# MEC1704Q register map
Vendor: Microchip Technology; Series: MEC1704; File version: 0
CPU: CM4 r1p0, little endian, MPU, FPU, 3 interrupt priority bits, 155 interrupts
Registers are 32-bit, read-write, reset 0x0 unless marked. A register's access mark holds for its fields unless they carry their own. Offsets are from the block's base; [hi:lo] are bit positions.

## RC_ID0 — This interface provides a single pin interface which can discriminate a number of quantized RC constants.
Base 0x40001400; register names take the prefix RC_ID_
Same registers: RC_ID1 0x40001480, RC_ID2 0x40001500
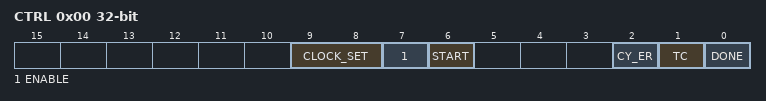
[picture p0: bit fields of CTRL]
0x00 CTRL — RC_ID Control Register
  [9:8] CLOCK_SET — This field selects the frequency of the Counter circuit clock. This field must retain the same value as long as the ENABLE bit in this register is 1.
  [7] ENABLE — Clearing the bit to 0 causes the RC_ID interface to enter the Reset state, gating its clocks, clearing the status bits in this register and entering into its lowest power state. Setting this bit to 1 causes the RC_ID interface to enter the Armed phase of an RC_ID measurement.
  [6] START — Setting this bit to 1 initiates the Discharged phase of an RC_ID measurement.
  [2] CY_ER — This bit is 1 if an RC_ID measurement encountered an error and the reading in the RC_ID Data Register is invalid. This bit is cleared to 0 when the RC_ID interface is in the Reset phase.
  [1] TC — This bit is cleared to 0 when the RC_ID interface is in the Reset phase, and set to 1 when the interface completes the Discharged phase of an RC_ID measurement.
  [0] DONE — This bit is cleared to 0 when the RC_ID interface is in the Reset phase, and set to 1 when the interface completes an RC_ID measurement.
0x04 DAT — Reads of this register provide the result of an RC_ID measurement.
  [15:0] RCID_DATA

## KMS — The Keyboard Scan Interface block provides a register interface to the EC to directly scan an external keyboard matrix of size up to 18x8.
Base 0x40009C00
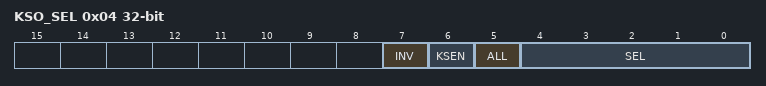
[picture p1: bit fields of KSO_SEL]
0x04 KSO_SEL — KSO Select and control
  [7] INV — 0= KSO[x] driven low when selected, 1= KSO[x] driven high when selected.
  [6] KSEN — 0= Keyboard scan enabled, 1= Keyboard scan disabled. All KSO output buffers disabled.
  [5] ALL — 0=When key scan is enabled, KSO output controlled by the KSO_SELECT field. 1=KSO[x] driven high when selected.
  [4:0] SEL — This field selects a KSO line (00000b = KSO[0] etc.) for output according to the value off KSO_INVERT in this register.
0x08 KSI ro — [7:0] This field returns the current state of the KSI pins.
0x0C KSI_STS — [7:0] Each bit in this field is set on the falling edge of the corresponding KSI input pin. A KSI interrupt is generated when its corresponding status bit and interrupt enable bit are both set. KSI interrupts are logically ORed together to produce KSC_INT and KSC_INT_WAKE. Writing a '1' to a bit will clear it. Writing a '0' to a bit has no effect.
0x10 KSI_IEN — [7:0] Each bit in KSI_IEN enables interrupt generation due to highto-low transition on a KSI input. An interrupt is generated when the corresponding bits in KSI_STATUS and KSI_INT_EN are both set.
0x14 EXT_CTRL — [0:0] PREDRIVE_ENABLE enables the. PREDRIVE mode to actively drive the KSO pins high for approximately 100ns before switching to open-drain operation. 0=Disable predrive on KSO pins. 1=Enable predrive on KSO pins.

## GP_SPI0 — The General Purpose Serial Peripheral Interface (GP-SPI) may be used to communicate with various peripheral devices, e.g., EEPROMS, DACs, ADCs, that use a standard Serial Peripheral Interface.
Base 0x40009400; register names take the prefix GP_SPI_
Same registers: GP_SPI1 0x40009480
0x00 ENABLE reset 0xF — [0:0] 1=Enabled. The device is fully operational. 0=Disabled. Clocks are gated to conserve power and the SPDOUT and SPI_CLK signals are set to their inactive state
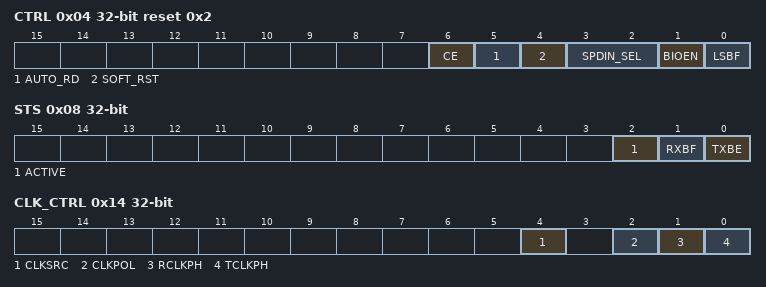
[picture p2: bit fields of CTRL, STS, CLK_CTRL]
0x04 CTRL reset 0x2 — SPI Control
  [6] CE — SPI Chip Select Enable. 1= SPI_CS# output signal is asserted, i.e., driven to logic '0' 0= SPI_CS# output signal is deasserted, i.e., driven to logic '1'
  [5] AUTO_RD — Auto Read Enable. 1=A read of the SPI RX_DATA Register will clear both the RXBF status bit and the TXBE status bit. 0=A read of the SPI RX_DATA Register will clear the RXBF status bit. The TXBE status bit will not be modified
  [4] SOFT_RST — Soft Reset is a self-clearing bit. Writing zero to this bit has no effect. Writing a one to this bit resets the entire SPI Interface, including all counters and registers back to their initial state.
  [3:2] SPDIN_SEL — [3:2] 1xb=SPDIN1 and SPDIN2. Select this option for Dual Mode [3:2] 01b=SPDIN2 only. Select this option for Half Duplex [3:2] 00b=SPDIN1 only. Select this option for Full Duplex
  [1] BIOEN — Bidirectional Output Enable control. 1=The SPDOUT_Direction signal configures the SPDOUT signal as an output. 0=The SPDOUT_Direction signal configures the SPDOUT signal as an input.
  [0] LSBF — Least Significant Bit First. 1= The data is transferred in LSB-first order. 0= The data is transferred in MSB-first order. (default)
0x08 STS ro — SPI Status
  [2] ACTIVE — ACTIVE status
  [1] RXBF — 1=RX_Data buffer is full, 0=RX_Data buffer is not full
  [0] TXBE — 1=TX_Data buffer is empty, 0=TX_Data buffer is not empty
0x0C TX_DAT — [7:0] A write to this register when the. Tx_Data buffer is empty (TXBE in the SPI Status Register is '1') initiates a SPI transaction.
0x10 RX_DAT — [7:0] This register is used to read the value returned by the external SPI device.
0x14 CLK_CTRL — SPI Clock Control. This register should not be changed during an active SPI transaction.
  [4] CLKSRC — 1=2MHz, 0=48 MHz Ring Oscillator
  [2] CLKPOL — 1=The SPI_CLK signal is high when the interface is idle and the first clock edge is a falling edge. 0=The SPI_CLK is low when the interface is idle and the first clock edge is a rising edge
  [1] RCLKPH — 1=Valid data on SPDIN signal is expected after the first SPI_CLK edge. This data is sampled on the second and following even SPI_CLK edges (i.e., sample data on falling edge) 0=Valid data is expected on the SPDIN signal on the first SPI_CLK edge. This data is sampled on the first and following odd SPI_-CLK edges (i.e., sample data on rising edge)
  [0] TCLKPH — 1=Valid data is clocked out on the first SPI_CLK edge on SPDOUT signal. The slave device should sample this data on the second and following even SPI_CLK edges (i.e., sample data on falling edge) 0=Valid data is clocked out on the SPDOUT signal prior to the first SPI_CLK edge. The slave device should sample this data on the first and following odd SPI_CLK edges (i.e., sample data on rising edge)
0x18 CLK_GEN reset 0x2 — [5:0] PRELOAD SPI Clock Generator Preload value.
  [5:0] PRLD — SPI Clock Generator Preload Value

## Notices in the file
Copyright (c) 2023 Microchip Technology Inc.
SPDX-License-Identifier: Apache-2.0
Licensed under the Apache License, Version 2.0 (the "License");
you may not use this file except in compliance with the License.
You may obtain a copy of the License at
http://www.apache.org/licenses/LICENSE-2.0
Unless required by applicable law or agreed to in writing, software
distributed under the License is distributed on an "AS IS" BASIS,
WITHOUT WARRANTIES OR CONDITIONS OF ANY KIND, either express or implied.
See the License for the specific language governing permissions and
limitations under the License.
